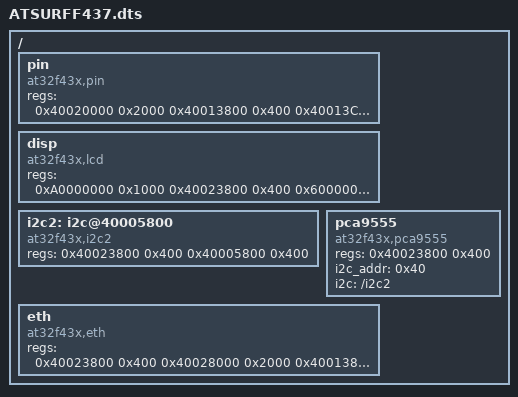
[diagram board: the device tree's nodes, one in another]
/dts-v1/;
/ {
	// usart0:usart_0 {
	// 	compatible = "st,usart";
	// 	regs = <0x0000000 0x1000>;
	// 	baud = <115200>;
	// 	stopbits = <1>;
	// };
	// log {
	// 	dev = <&usart0>;
	// };
	pin {
		compatible = "at32f43x,pin";
		regs = <
		0x40020000 0x2000 /*GPIO*/
		0x40013800 0x400  /*EXINT & SCFG*/
		0x40013C00 0x400  /*EXINT & SCFG*/
		0x40023800 0x400  /*CRM*/
		>;
	};
	disp {
		compatible = "at32f43x,lcd";
		regs = <
		0xA0000000 0x1000 /*XMC_REG*/
		0x40023800 0x400  /*CRM*/
		0x60000000 0x100000  /*XMC_MEM*/
		>;
	};
	i2c2:i2c@40005800 {
		compatible = "at32f43x,i2c2";
		regs = <
		0x40023800 0x400  /*CRM*/
		0x40005800 0x400 /*I2C2*/
		>;
	};
	pca9555 {
		compatible = "at32f43x,pca9555";
		regs = <0x40023800 0x400>; /*CRM*/
		i2c_addr = <0x40>; /*i2c addr*/
		// i2c = <&i2c2>;
		i2c = "/i2c2";
	};
	eth {
		compatible = "at32f43x,eth";
		regs = <
		0x40023800 0x400 /*CRM*/
		0x40028000 0x2000 /*EMAC*/
		0x40013800 0x400  /*EXINT & SCFG*/
		0x40013C00 0x400  /*EXINT & SCFG*/
		>;
	};
};
